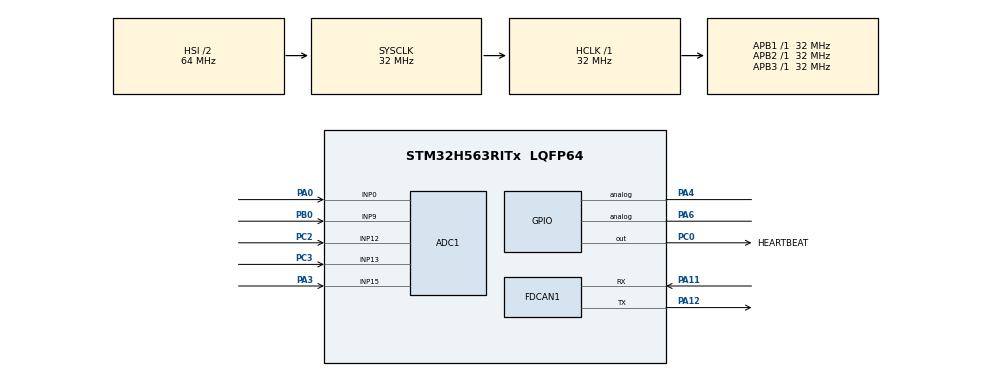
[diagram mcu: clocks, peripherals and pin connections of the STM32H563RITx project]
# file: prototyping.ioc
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ADC1.Channel-2\#ChannelRegularConversion=ADC_CHANNEL_9
ADC1.MonitoredBy-2\#ChannelRegularConversion=__NULL
ADC1.NbrOfConversionFlag=1
ADC1.OffsetNumber-2\#ChannelRegularConversion=ADC_OFFSET_NONE
ADC1.Rank-2\#ChannelRegularConversion=1
ADC1.SamplingTime-2\#ChannelRegularConversion=ADC_SAMPLETIME_2CYCLES_5
ADC1.master=1
BOOTPATH.BootPathName=LEGACY
BOOTPATH.UserSelectedBootPath=LEGACY
CORTEX_M33_NS.Number-Cortex_Memory_Protection_Unit_Region0_OTP_RO_AREAS_Settings=MPU_REGION_NUMBER0
CORTEX_M33_NS.default_mode_Activation=1
CORTEX_M33_NS.userName=CORTEX_M33
FDCAN1.CalculateBaudRateNominal=125000
FDCAN1.CalculateTimeBitNominal=8000
FDCAN1.CalculateTimeQuantumNominal=500.0
FDCAN1.NominalTimeSeg1=8
FDCAN1.NominalTimeSeg2=7
Mcu.Family=STM32H5
Mcu.Name=STM32H563RITx
Mcu.Package=LQFP64
NVIC.FDCAN1_IT0_IRQn=true\:0\:0\:false\:false\:true\:true\:true\:true
NVIC.PriorityGroup=NVIC_PRIORITYGROUP_4
PA0.Signal=ADCx_INP0
PA11.Mode=FDCAN_Activate
PA11.Signal=FDCAN1_RX
PA12.Mode=FDCAN_Activate
PA12.Signal=FDCAN1_TX
PA13(JTMS/SWDIO).Mode=Trace_Asynchronous_SW
PA13(JTMS/SWDIO).Signal=DEBUG_JTMS-SWDIO
PA14(JTCK/SWCLK).Mode=Trace_Asynchronous_SW
PA14(JTCK/SWCLK).Signal=DEBUG_JTCK-SWCLK
PA3.Signal=ADCx_INP15
PA4.Signal=SharedAnalog_PA4
PA6.Signal=SharedAnalog_PA6
PB0.Signal=ADCx_INP9
PB3(JTDO/TRACESWO).Mode=Trace_Asynchronous_SW
PB3(JTDO/TRACESWO).Signal=DEBUG_JTDO-SWO
PC0.GPIO_Label=HEARTBEAT
PC0.Signal=GPIO_Output
PC2.Signal=SharedAnalog_PC2
PC3.Signal=ADCx_INP13
ProjectManager.HeapSize=0x200
ProjectManager.StackSize=0x400
ProjectManager.TargetToolchain=STM32CubeIDE
RCC.ADCFreq_Value=32000000
RCC.AHBFreq_Value=32000000
RCC.APB1Freq_Value=32000000
RCC.APB1TimFreq_Value=32000000
RCC.APB2Freq_Value=32000000
RCC.APB2TimFreq_Value=32000000
RCC.APB3Freq_Value=32000000
RCC.CSI_VALUE=4000000
RCC.CortexFreq_Value=32000000
RCC.EPOD_VALUE=4000000
RCC.FDCANClockSelection=RCC_FDCANCLKSOURCE_PLL2Q
RCC.HCLKFreq_Value=32000000
RCC.HSE_VALUE=25000000
RCC.HSI48_VALUE=48000000
RCC.HSI_VALUE=64000000
RCC.LSE_VALUE=32768
RCC.LSIRC_VALUE=32000
RCC.PLL1Q=6
RCC.PLL2FRACN=0
RCC.PLL2N=32
RCC.PLL2Q=4
RCC.SYSCLKFreq_VALUE=32000000
RCC.USBFreq_Value=48000000
RCC.VCOOutputFreq_Value=516000000
SH.ADCx_INP0.0=ADC1_INP0,IN0-Single-Ended
SH.ADCx_INP13.0=ADC1_INP13,IN13-Single-Ended
SH.ADCx_INP15.0=ADC1_INP15,IN15-Single-Ended
SH.ADCx_INP9.0=ADC1_INP9,IN9-Single-Ended
SH.SharedAnalog_PA4.0=GPIO_Analog
SH.SharedAnalog_PA4.1=ADC1_INP18
SH.SharedAnalog_PA6.0=GPIO_Analog
SH.SharedAnalog_PA6.1=ADC1_INP3
SH.SharedAnalog_PC2.0=GPIO_Analog
SH.SharedAnalog_PC2.1=ADC1_INP12,IN12-Single-Ended
VP_BOOTPATH_VS_BOOTPATH.Mode=BP_Activate
VP_CORTEX_M33_NS_VS_Hclk.Mode=Hclk_Mode
VP_ICACHE_VS_ICACHE.Mode=DirectMappedCache
VP_MEMORYMAP_VS_MEMORYMAP.Mode=CurAppReg
VP_PWR_VS_LPOM.Mode=PowerOptimisation
VP_PWR_VS_SECSignals.Mode=Security/Privilege
board=custom

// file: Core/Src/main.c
/* USER CODE BEGIN Header */
/**
  ******************************************************************************
  * @file           : main.c
  * @brief          : Main program body
  ******************************************************************************
  * @attention
  *
  * Copyright (c) 2026 STMicroelectronics.
  * All rights reserved.
  *
  * This software is licensed under terms that can be found in the LICENSE file
  * in the root directory of this software component.
  * If no LICENSE file comes with this software, it is provided AS-IS.
  *
  ******************************************************************************
  */
/* USER CODE END Header */
#include "main.h"

/* USER CODE BEGIN Includes */
#include <stdio.h>
/* USER CODE END Includes */

ADC_HandleTypeDef hadc1;

FDCAN_HandleTypeDef hfdcan1;

void SystemClock_Config(void);
static void MPU_Config(void);
static void MX_GPIO_Init(void);
static void MX_FDCAN1_Init(void);
static void MX_ICACHE_Init(void);
static void MX_ADC1_Init(void);

/* USER CODE BEGIN 0 */
uint32_t getADCValue( uint32_t channel);

/* USER CODE END 0 */

int main(void)
{

  /* MCU Configuration--------------------------------------------------------*/

  /* MPU Configuration--------------------------------------------------------*/
  MPU_Config();

  /* Reset of all peripherals, Initializes the Flash interface and the Systick. */
  HAL_Init();

  /* Configure the system clock */
  SystemClock_Config();

  /* Initialize all configured peripherals */
  MX_GPIO_Init();
  MX_FDCAN1_Init();
  MX_ICACHE_Init();
  MX_ADC1_Init();
  /* USER CODE BEGIN 2 */

  HAL_ADCEx_Calibration_Start(&hadc1, ADC_SINGLE_ENDED);
  uint32_t adcValue;
  uint32_t voltage;
  const uint32_t slope;
  const uint32_t b;

  /* USER CODE END 2 */

  /* Infinite loop */
  /* USER CODE BEGIN WHILE */
  while (1)
  {
	  adcValue = getADCValue(ADC_CHANNEL_12);
	  HAL_Delay(100);				//add other channels
	  printf("Pin1: %d \n", adcValue);
	  	  //put in math
	  	 /* printf("%d Volts\n", voltage);
	  	  getADCValue(ADC_CHANNEL_12);
	  	  HAL_Delay(100);
    /* USER CODE END WHILE */

  }
}

void SystemClock_Config(void)
{
  RCC_OscInitTypeDef RCC_OscInitStruct = {0};
  RCC_ClkInitTypeDef RCC_ClkInitStruct = {0};

  /** Configure the main internal regulator output voltage
  */
  __HAL_PWR_VOLTAGESCALING_CONFIG(PWR_REGULATOR_VOLTAGE_SCALE3);

  while(!__HAL_PWR_GET_FLAG(PWR_FLAG_VOSRDY)) {}

  /** Initializes the RCC Oscillators according to the specified parameters
  * in the RCC_OscInitTypeDef structure.
  */
  RCC_OscInitStruct.OscillatorType = RCC_OSCILLATORTYPE_HSI|RCC_OSCILLATORTYPE_CSI;
  RCC_OscInitStruct.HSIState = RCC_HSI_ON;
  RCC_OscInitStruct.HSIDiv = RCC_HSI_DIV2;
  RCC_OscInitStruct.HSICalibrationValue = RCC_HSICALIBRATION_DEFAULT;
  RCC_OscInitStruct.CSIState = RCC_CSI_ON;
  RCC_OscInitStruct.CSICalibrationValue = RCC_CSICALIBRATION_DEFAULT;
  RCC_OscInitStruct.PLL.PLLState = RCC_PLL_NONE;
  if (HAL_RCC_OscConfig(&RCC_OscInitStruct) != HAL_OK)
  {
    Error_Handler();
  }

  /** Initializes the CPU, AHB and APB buses clocks
  */
  RCC_ClkInitStruct.ClockType = RCC_CLOCKTYPE_HCLK|RCC_CLOCKTYPE_SYSCLK
                              |RCC_CLOCKTYPE_PCLK1|RCC_CLOCKTYPE_PCLK2
                              |RCC_CLOCKTYPE_PCLK3;
  RCC_ClkInitStruct.SYSCLKSource = RCC_SYSCLKSOURCE_HSI;
  RCC_ClkInitStruct.AHBCLKDivider = RCC_SYSCLK_DIV1;
  RCC_ClkInitStruct.APB1CLKDivider = RCC_HCLK_DIV1;
  RCC_ClkInitStruct.APB2CLKDivider = RCC_HCLK_DIV1;
  RCC_ClkInitStruct.APB3CLKDivider = RCC_HCLK_DIV1;

  if (HAL_RCC_ClockConfig(&RCC_ClkInitStruct, FLASH_LATENCY_1) != HAL_OK)
  {
    Error_Handler();
  }

  /** Configure the programming delay
  */
  __HAL_FLASH_SET_PROGRAM_DELAY(FLASH_PROGRAMMING_DELAY_0);
}

static void MX_ADC1_Init(void)
{

  ADC_ChannelConfTypeDef sConfig = {0};
  //ADC_ChannelConfTypeDef sConfig2 = {12};

  /** Common config
  */
  hadc1.Instance = ADC1;
  hadc1.Init.ClockPrescaler = ADC_CLOCK_ASYNC_DIV1;
  hadc1.Init.Resolution = ADC_RESOLUTION_12B;
  hadc1.Init.DataAlign = ADC_DATAALIGN_RIGHT;
  hadc1.Init.ScanConvMode = ADC_SCAN_DISABLE;
  hadc1.Init.EOCSelection = ADC_EOC_SINGLE_CONV;
  hadc1.Init.LowPowerAutoWait = DISABLE;
  hadc1.Init.ContinuousConvMode = DISABLE;
  hadc1.Init.NbrOfConversion = 1;
  hadc1.Init.DiscontinuousConvMode = DISABLE;
  hadc1.Init.ExternalTrigConv = ADC_SOFTWARE_START;
  hadc1.Init.ExternalTrigConvEdge = ADC_EXTERNALTRIGCONVEDGE_NONE;
  hadc1.Init.DMAContinuousRequests = DISABLE;
  hadc1.Init.SamplingMode = ADC_SAMPLING_MODE_NORMAL;
  hadc1.Init.Overrun = ADC_OVR_DATA_PRESERVED;
  hadc1.Init.OversamplingMode = DISABLE;
  if (HAL_ADC_Init(&hadc1) != HAL_OK)
  {
    Error_Handler();
  }

  /** Configure Regular Channel
  */
  sConfig.Channel = ADC_CHANNEL_0;
  sConfig.Rank = ADC_REGULAR_RANK_1;
  sConfig.SamplingTime = ADC_SAMPLETIME_2CYCLES_5;
  sConfig.SingleDiff = ADC_SINGLE_ENDED;
  sConfig.OffsetNumber = ADC_OFFSET_NONE;
  sConfig.Offset = 0;
  if (HAL_ADC_ConfigChannel(&hadc1, &sConfig) != HAL_OK)
  {
    Error_Handler();
  }

}

static void MX_FDCAN1_Init(void)
{

  hfdcan1.Instance = FDCAN1;
  hfdcan1.Init.ClockDivider = FDCAN_CLOCK_DIV1;
  hfdcan1.Init.FrameFormat = FDCAN_FRAME_CLASSIC;
  hfdcan1.Init.Mode = FDCAN_MODE_NORMAL;
  hfdcan1.Init.AutoRetransmission = DISABLE;
  hfdcan1.Init.TransmitPause = DISABLE;
  hfdcan1.Init.ProtocolException = DISABLE;
  hfdcan1.Init.NominalPrescaler = 16;
  hfdcan1.Init.NominalSyncJumpWidth = 1;
  hfdcan1.Init.NominalTimeSeg1 = 8;
  hfdcan1.Init.NominalTimeSeg2 = 7;
  hfdcan1.Init.DataPrescaler = 1;
  hfdcan1.Init.DataSyncJumpWidth = 1;
  hfdcan1.Init.DataTimeSeg1 = 1;
  hfdcan1.Init.DataTimeSeg2 = 1;
  hfdcan1.Init.StdFiltersNbr = 0;
  hfdcan1.Init.ExtFiltersNbr = 0;
  hfdcan1.Init.TxFifoQueueMode = FDCAN_TX_FIFO_OPERATION;
  if (HAL_FDCAN_Init(&hfdcan1) != HAL_OK)
  {
    Error_Handler();
  }

}

static void MX_ICACHE_Init(void)
{

  /** Enable instruction cache in 1-way (direct mapped cache)
  */
  if (HAL_ICACHE_ConfigAssociativityMode(ICACHE_1WAY) != HAL_OK)
  {
    Error_Handler();
  }
  if (HAL_ICACHE_Enable() != HAL_OK)
  {
    Error_Handler();
  }

}

static void MX_GPIO_Init(void)
{
  GPIO_InitTypeDef GPIO_InitStruct = {0};

  /* GPIO Ports Clock Enable */
  __HAL_RCC_GPIOC_CLK_ENABLE();
  __HAL_RCC_GPIOA_CLK_ENABLE();
  __HAL_RCC_GPIOB_CLK_ENABLE();

  /*Configure GPIO pin Output Level */
  HAL_GPIO_WritePin(HEARTBEAT_GPIO_Port, HEARTBEAT_Pin, GPIO_PIN_RESET);

  /*Configure GPIO pin : HEARTBEAT_Pin */
  GPIO_InitStruct.Pin = HEARTBEAT_Pin;
  GPIO_InitStruct.Mode = GPIO_MODE_OUTPUT_PP;
  GPIO_InitStruct.Pull = GPIO_NOPULL;
  GPIO_InitStruct.Speed = GPIO_SPEED_FREQ_LOW;
  HAL_GPIO_Init(HEARTBEAT_GPIO_Port, &GPIO_InitStruct);

}

/* USER CODE BEGIN 4 */
uint32_t getADCValue(uint32_t channel)
{
	uint32_t value;

	ADC_ChannelConfTypeDef sConfig2 = {0};

	sConfig2.Channel = channel;
	sConfig2.Rank = ADC_REGULAR_RANK_1;
	sConfig2.SamplingTime = ADC_SAMPLETIME_2CYCLES_5;
	sConfig2.SingleDiff = ADC_SINGLE_ENDED;
	sConfig2.OffsetNumber = ADC_OFFSET_NONE;
	sConfig2.Offset = 0;
	HAL_ADC_ConfigChannel(&hadc1, &sConfig2);
	HAL_StatusTypeDef flag;
	HAL_ADC_Start(&hadc1);//start conversion
	flag = HAL_ADC_PollForConversion(&hadc1, 1000);//wait ntil statu flag giveas the ok
	if(flag == HAL_OK)
	{
		value = HAL_ADC_GetValue(&hadc1);
	}

	HAL_ADC_Stop(&hadc1);

	return value;
}
/* USER CODE END 4 */

 /* MPU Configuration */

void MPU_Config(void)
{
  MPU_Region_InitTypeDef MPU_InitStruct = {0};
  MPU_Attributes_InitTypeDef MPU_AttributesInit = {0};

  /* Disables the MPU */
  HAL_MPU_Disable();

  /** Initializes and configures the Region 0 and the memory to be protected
  */
  MPU_InitStruct.Enable = MPU_REGION_ENABLE;
  MPU_InitStruct.Number = MPU_REGION_NUMBER0;
  MPU_InitStruct.BaseAddress = 0x08FFF000;
  MPU_InitStruct.LimitAddress = 0x08FFFFFF;
  MPU_InitStruct.AttributesIndex = MPU_ATTRIBUTES_NUMBER0;
  MPU_InitStruct.AccessPermission = MPU_REGION_ALL_RO;
  MPU_InitStruct.DisableExec = MPU_INSTRUCTION_ACCESS_DISABLE;
  MPU_InitStruct.IsShareable = MPU_ACCESS_NOT_SHAREABLE;

  HAL_MPU_ConfigRegion(&MPU_InitStruct);

  /** Initializes and configures the Attribute 0 and the memory to be protected
  */
  MPU_AttributesInit.Number = MPU_ATTRIBUTES_NUMBER0;
  MPU_AttributesInit.Attributes = INNER_OUTER(MPU_NOT_CACHEABLE);

  HAL_MPU_ConfigMemoryAttributes(&MPU_AttributesInit);
  /* Enables the MPU */
  HAL_MPU_Enable(MPU_PRIVILEGED_DEFAULT);

}

void Error_Handler(void)
{
  __disable_irq();
  while (1)
  {
  }
}
